AUTOSAR XML (schema 4-3-0)
package /ComponentTypes
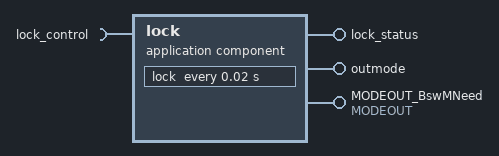
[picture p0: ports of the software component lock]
  application sw component type lock
    provide port lock_status: nonqueued-sender-com-spec{data-element=lock_status, init-value=0}, provided-interface=lock_status
    require port lock_control: nonqueued-receiver-com-spec{data-element=lock_cmd, init-value=0}, required-interface=lock_control
    provide port outmode: nonqueued-sender-com-spec=mode, provided-interface=outmode
    provide port MODEOUT_BswMNeed: nonqueued-sender-com-spec=MODE, provided-interface=MODEOUT
    behavior lock_InternalBehavior
      timing event TMT_Runnable: start-on-event=lock, period=0.02
      runnable lock: minimum-start-interval=0.02
        data-receive-point-by-arguments:
          access REC_lock_control_lock_cmd: accessed-variable=lock_control.lock_cmd
        data-send-points:
          access SEND_lock_status_lock_status: accessed-variable=lock_status.lock_status
      swc service dependency BswMNeed: assigned-ports=role-based-port-assignment={port-prototype=MODEOUT_BswMNeed, role=MODEOUT}
        service-needs:
          bsw mgr needs BswMNeed
      swc service dependency SupervisedEntityNeed
        service-needs:
          supervised entity needs SupervisedEntityNeed: activate-at-start=false, enable-deactivation=false, expected-alive-cycle=0, max-alive-cycle=0, min-alive-cycle=0, tolerated-failed-cycles=0
  swc implementation lock_Implementation: behavior=lock_InternalBehavior
